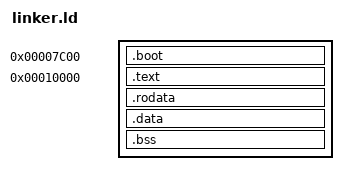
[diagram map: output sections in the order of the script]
OUTPUT_FORMAT("binary")
OUTPUT_ARCH(i386:x86-64)

ENTRY(start)

SECTIONS
{
    . = 0x7C00;
    .boot :
    {
        *(.boot)
    }

    . = 0x10000;
    .text ALIGN(16) :
    {
        *(.text)
        *(.text.*)
    }

    .rodata ALIGN(16) :
    {
        *(.rodata)
        *(.rodata.*)
    }

    .data ALIGN(16) :
    {
        *(.data)
        *(.data.*)
    }

    .bss ALIGN(16) :
    {
        _bss_start = .;
        *(COMMON)
        *(.bss)
        *(.bss.*)
        _bss_end = .;
    }

    _kernel_end = .;

    /DISCARD/ :
    {
        *(.eh_frame)
        *(.comment)
        *(.note*)
    }
}
